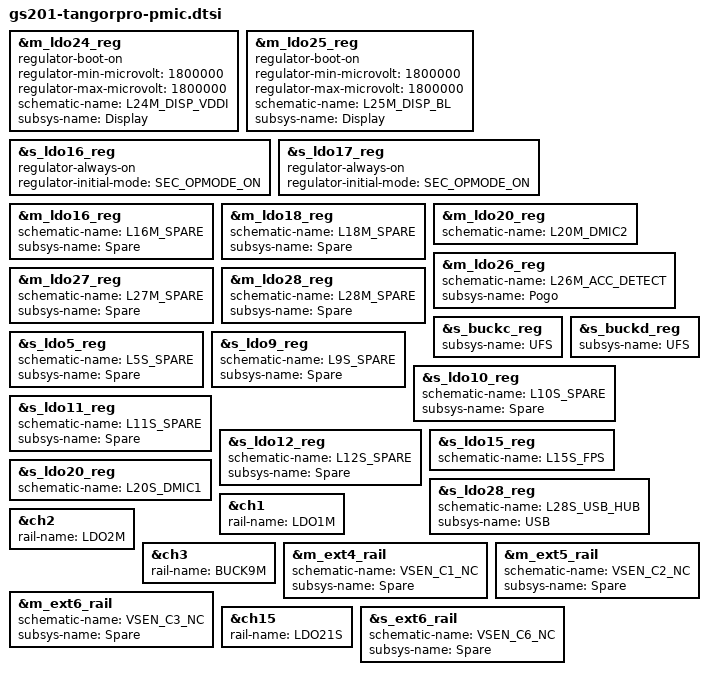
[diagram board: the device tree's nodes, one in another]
// SPDX-License-Identifier: GPL-2.0-only
/*
 * Tangorpro-specific PMIC settings
 *
 * Copyright 2022 Google LLC.
 *
 */

/* Display: vddi-supply voltage */
&m_ldo24_reg {
	regulator-boot-on;
	regulator-min-microvolt = <1800000>;
	regulator-max-microvolt = <1800000>;
	schematic-name = "L24M_DISP_VDDI";
	subsys-name = "Display";
};

/* Display: backlight enable */
&m_ldo25_reg {
	regulator-boot-on;
	/delete-property/ regulator-always-on;
	regulator-min-microvolt = <1800000>;
	regulator-max-microvolt = <1800000>;
	schematic-name = "L25M_DISP_BL";
	subsys-name = "Display";
};

/* UWB: Ravenclaw and Tangorpro use LDO[16,17]S for UWB */
&s_ldo16_reg {
	regulator-always-on;
	regulator-initial-mode = <SEC_OPMODE_ON>;
};

/* UWB: Ravenclaw and Tangorpro use LDO[16,17]S for UWB */
&s_ldo17_reg {
	regulator-always-on;
	regulator-initial-mode = <SEC_OPMODE_ON>;
};

&m_ldo16_reg {
	schematic-name = "L16M_SPARE";
	subsys-name = "Spare";
};

&m_ldo18_reg {
	schematic-name = "L18M_SPARE";
	subsys-name = "Spare";
};

&m_ldo20_reg {
	schematic-name = "L20M_DMIC2";
};

&m_ldo24_reg {
	schematic-name = "L24M_DISP_VDDI";
	subsys-name = "Display";
};

&m_ldo26_reg {
	schematic-name = "L26M_ACC_DETECT";
	subsys-name = "Pogo";
};

&m_ldo27_reg {
	schematic-name = "L27M_SPARE";
	subsys-name = "Spare";
};

&m_ldo28_reg {
	schematic-name = "L28M_SPARE";
	subsys-name = "Spare";
};

&s_buckc_reg {
	subsys-name = "UFS";
};

&s_buckd_reg {
	subsys-name = "UFS";
};

&s_ldo5_reg {
	schematic-name = "L5S_SPARE";
	subsys-name = "Spare";
};

&s_ldo9_reg {
	schematic-name = "L9S_SPARE";
	subsys-name = "Spare";
};

&s_ldo10_reg {
	schematic-name = "L10S_SPARE";
	subsys-name = "Spare";
};

&s_ldo11_reg {
	schematic-name = "L11S_SPARE";
	subsys-name = "Spare";
};

&s_ldo12_reg {
	schematic-name = "L12S_SPARE";
	subsys-name = "Spare";
};

&s_ldo15_reg {
	schematic-name = "L15S_FPS";
};

&s_ldo20_reg {
	schematic-name = "L20S_DMIC1";
};

&s_ldo28_reg {
	schematic-name = "L28S_USB_HUB";
	subsys-name = "USB";
};

/* No modem on Tangor Pro */
/* replace VSYS_PWR_MMWAVE to L1M_ALIVE */
&ch1 {
	rail-name = "LDO1M";
};

/* replace VSYS_PWR_MODEM to L2M_ALIVE */
&ch2 {
	rail-name = "LDO2M";
};

/* replace VSYS_PWR_RFFE to S9M_LLDO3 */
&ch3 {
	rail-name = "BUCK9M";
};

&m_ext4_rail {
	schematic-name = "VSEN_C1_NC";
	subsys-name = "Spare";
};

&m_ext5_rail {
	schematic-name = "VSEN_C2_NC";
	subsys-name = "Spare";
};

&m_ext6_rail {
	schematic-name = "VSEN_C3_NC";
	subsys-name = "Spare";
};

/* replace VSYS_PWR_CAM to L21S_VDD2L_MEM */
&ch15 {
	rail-name = "LDO21S";
};

&s_ext6_rail {
	schematic-name = "VSEN_C6_NC";
	subsys-name = "Spare";
};

/* Unused */
&m_ldo18_reg {
	/delete-property/ regulator-always-on;
};

/* Unused */
&m_ldo26_reg {
	/delete-property/ regulator-always-on;
};

/* Unused */
&s_ldo5_reg {
	/delete-property/ regulator-boot-on;
};

/* Unused */
&s_ldo9_reg {
	/delete-property/ regulator-always-on;
};

/* Unused */
&s_ldo10_reg {
	/delete-property/ regulator-always-on;
};

/* Unused */
&s_ldo11_reg {
	/delete-property/ regulator-always-on;
};
